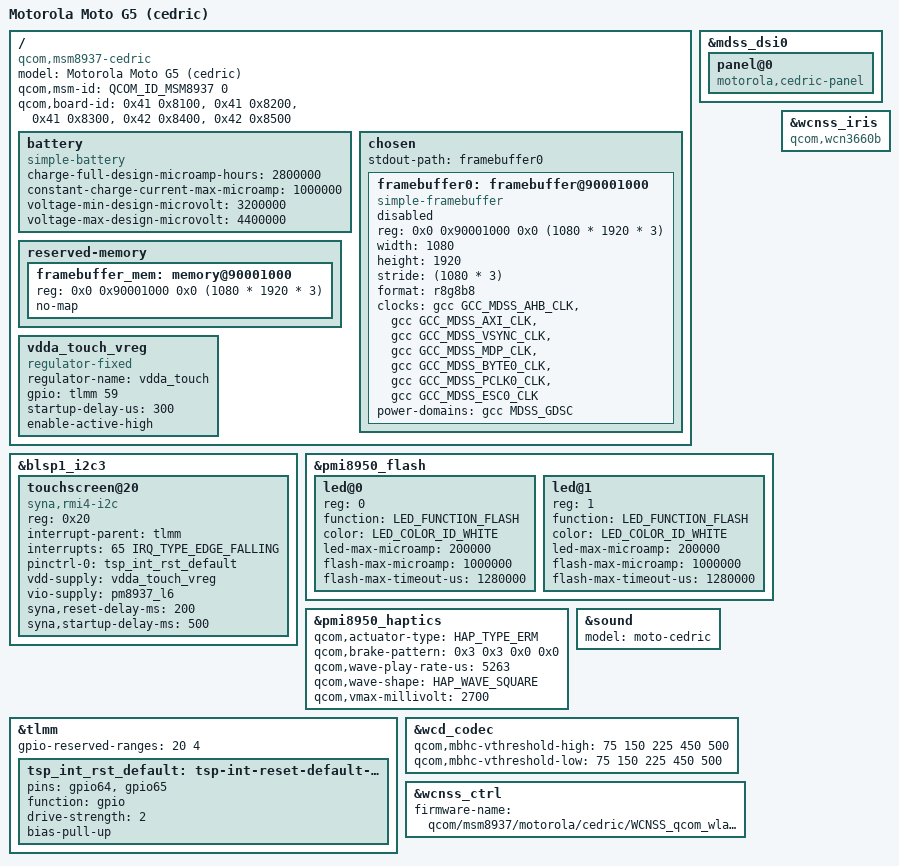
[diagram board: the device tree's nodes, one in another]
// SPDX-License-Identifier: BSD-3-Clause

/dts-v1/;

#include "msm8937.dtsi"
#include "msm8937-msm8917-motorola-common.dtsi"

/ {
	model = "Motorola Moto G5 (cedric)";
	compatible = "qcom,msm8937-cedric", "qcom-msm8937-moto",
		"motorola,cedric", "qcom,msm8937";
	qcom,msm-id = <QCOM_ID_MSM8937 0>;
	qcom,board-id = <0x41 0x8100>,
			<0x41 0x8200>,
			<0x41 0x8300>,
			<0x42 0x8400>,
			<0x42 0x8500>;

	battery: battery {
		compatible = "simple-battery";

		charge-full-design-microamp-hours = <2800000>;
		constant-charge-current-max-microamp = <1000000>;
		voltage-min-design-microvolt = <3200000>;
		voltage-max-design-microvolt = <4400000>;
	};

	chosen {
		#address-cells = <2>;
		#size-cells = <2>;
		ranges;

		stdout-path = "framebuffer0";

		framebuffer0: framebuffer@90001000 {
			compatible = "simple-framebuffer";
			reg = <0x0 0x90001000 0x0 (1080 * 1920 * 3)>;
			width = <1080>;
			height = <1920>;
			stride = <(1080 * 3)>;
			format = "r8g8b8";

			clocks = <&gcc GCC_MDSS_AHB_CLK>,
				 <&gcc GCC_MDSS_AXI_CLK>,
				 <&gcc GCC_MDSS_VSYNC_CLK>,
				 <&gcc GCC_MDSS_MDP_CLK>,
				 <&gcc GCC_MDSS_BYTE0_CLK>,
				 <&gcc GCC_MDSS_PCLK0_CLK>,
				 <&gcc GCC_MDSS_ESC0_CLK>;
			power-domains = <&gcc MDSS_GDSC>;
			status = "disabled";
		};
	};

	reserved-memory {
		framebuffer_mem: memory@90001000 {
			reg = <0x0 0x90001000 0x0 (1080 * 1920 * 3)>;
			no-map;
		};
	};

	vdda_touch_vreg: vdda_touch_vreg {
		compatible = "regulator-fixed";
		regulator-name = "vdda_touch";
		gpio = <&tlmm 59 GPIO_ACTIVE_HIGH>;
		startup-delay-us = <300>;
		enable-active-high;
	};
};

&blsp1_i2c3 {
	status = "okay";

	touchscreen@20 {
		compatible = "syna,rmi4-i2c";
		reg = <0x20>;

		interrupt-parent = <&tlmm>;
		interrupts = <65 IRQ_TYPE_EDGE_FALLING>;

		pinctrl-0 = <&tsp_int_rst_default>;
		pinctrl-names = "default";

		vdd-supply = <&vdda_touch_vreg>;
		vio-supply = <&pm8937_l6>;

		syna,reset-delay-ms = <200>;
		syna,startup-delay-ms = <500>;
	};
};

&mdss_dsi0 {
	panel@0 {
		compatible = "motorola,cedric-panel";
	};
};

&pmi8950_flash {
	#address-cells = <1>;
	#size-cells = <0>;
	status = "okay";

	led@0 {
		reg = <0>;
		function = LED_FUNCTION_FLASH;
		color = <LED_COLOR_ID_WHITE>;
		led-max-microamp = <200000>;
		flash-max-microamp = <1000000>;
		flash-max-timeout-us = <1280000>;
	};

	led@1 {
		reg = <1>;
		function = LED_FUNCTION_FLASH;
		color = <LED_COLOR_ID_WHITE>;
		led-max-microamp = <200000>;
		flash-max-microamp = <1000000>;
		flash-max-timeout-us = <1280000>;
	};
};

&pmi8950_haptics {
	qcom,actuator-type = <HAP_TYPE_ERM>;
	qcom,brake-pattern = <0x3 0x3 0x0 0x0>;
	qcom,wave-play-rate-us = <5263>;
	qcom,wave-shape = <HAP_WAVE_SQUARE>;
	qcom,vmax-millivolt = <2700>;

	status = "okay";
};

&sound {
	model = "moto-cedric";
};

&tlmm {
	gpio-reserved-ranges = <20 4>;

	tsp_int_rst_default: tsp-int-reset-default-state {
		pins = "gpio64", "gpio65";
		function = "gpio";
		drive-strength = <2>;
		bias-pull-up;
	};
};

&wcd_codec {
	qcom,mbhc-vthreshold-high = <75 150 225 450 500>;
	qcom,mbhc-vthreshold-low = <75 150 225 450 500>;
};

&wcnss_ctrl {
	firmware-name = "qcom/msm8937/motorola/cedric/WCNSS_qcom_wlan_nv.bin";
};

&wcnss_iris {
	compatible = "qcom,wcn3660b";
};
